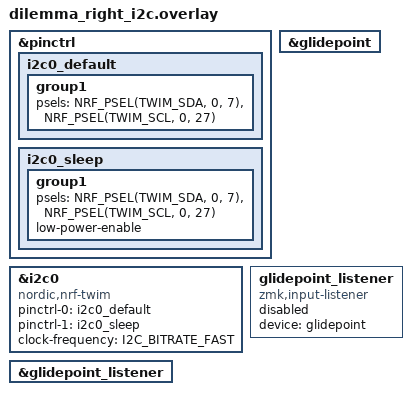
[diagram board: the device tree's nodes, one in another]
/*
 * Copyright (c) 2021 The ZMK Contributors
 *
 * SPDX-License-Identifier: MIT
 */

#include <input/processors.dtsi>
#include "dilemma_right_i2c.dtsi"

&pinctrl {
    /* configuration for i2c0 device, default state */
    i2c0_default: i2c0_default {
        group1 {
            psels = <NRF_PSEL(TWIM_SDA, 0, 7)>,
                <NRF_PSEL(TWIM_SCL, 0, 27)>;
        };
    };

    i2c0_sleep: i2c0_sleep {
        group1 {
            psels = <NRF_PSEL(TWIM_SDA, 0, 7)>,
                <NRF_PSEL(TWIM_SCL, 0, 27)>;
            low-power-enable;
        };
    };
};

// Custom I2C config
&i2c0 {
    compatible = "nordic,nrf-twim"; // I2C controller instead of generic
    status = "okay";
    pinctrl-0 = <&i2c0_default>;
    pinctrl-1 = <&i2c0_sleep>;
    pinctrl-names = "default", "sleep";
    clock-frequency = <I2C_BITRATE_FAST>;
};

// Cirque Trackpad on the Right side, no matter which side is central

&glidepoint {
	status = "okay";
};

// Cirque Trackpad, if the Left side is central, comment otherwise

// &glidepoint_split {
// 	device = <&glidepoint>;
// };

// Cirque Trackpad on the Right side, no matter which side is central
glidepoint_listener: glidepoint_listener {
	compatible = "zmk,input-listener";
	status = "disabled";
	device = <&glidepoint>;
};

// Cirtque Trackpad, if the Right side is central, comment otherwise

&glidepoint_listener {
    status = "okay";
};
